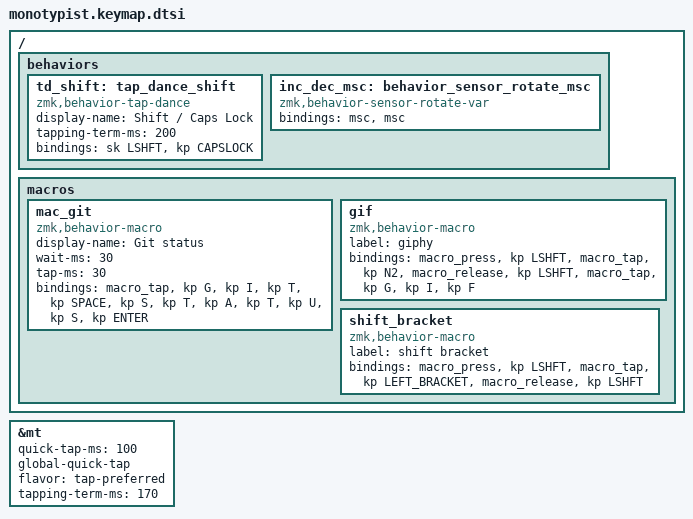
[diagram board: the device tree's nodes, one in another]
/*
 *     __  __                  _____            _     _ 
 *    |  \/  | ___  _ __   ___|_   _|   _ _ __ (_)___| |_ 
 *    | |\/| |/ _ \| '_ \ / _ \ | || | | | '_ \| / __| __|
 *    | |  | | (_) | | | | (_) || || |_| | (_) | \__ \ |_ 
 *    |_|  |_|\___/|_| |_|\___/ |_| \__, | .__/|_|___/\__|
 *    \_______________________/     |___/|_|              
 *
 * The keymap every MonoTypist language shares: behaviours, macros, and the two generated parts of one
 * language. A language's keymap (config/boards/shields/v4_2_<lang>/v4_2_<lang>.keymap, itself written by
 * tools/gen-keymap.mjs) names those parts in MT_COMBOS and MT_LAYERS and then includes this file.
 */

#if !defined(MT_COMBOS) || !defined(MT_LAYERS)
#error "Include this file from a language's keymap, which defines MT_COMBOS and MT_LAYERS"
#endif

#include <behaviors.dtsi>
#include <behaviors/lpos.dtsi>
#include <dt-bindings/zmk/keys.h>
#include <dt-bindings/zmk/pointing.h>
#include <dt-bindings/zmk/bt.h>
#include <dt-bindings/zmk/outputs.h>

#ifndef SIMPLE_MODE
#define SIMPLE_MODE 0
#endif

#define BASE 0
#define BLUE 1
#define RED 2
#define ORANGE 3
#define NAV  4
#define SYM  5
#define ADJ  6

&mt {
  quick-tap-ms = <100>;
  global-quick-tap;
  flavor = "tap-preferred";
  tapping-term-ms = <170>;
};

/ {
    // The language's combos, generated from layout/<lang>.json: every "letter key + thumb key".
    #include MT_COMBOS
//   combos {
//           compatible = "zmk,combos";
//           combo_esc {
//               timeout-ms = <50>;
//               key-positions = <0 1>;
//               bindings = <&kp ESC>;
//           };
//   };


    behaviors {
        td_shift: tap_dance_shift {
            compatible = "zmk,behavior-tap-dance";
            display-name = "Shift / Caps Lock"; // the name ZMK Studio and the site's editor know it by
            #binding-cells = <0>;
            tapping-term-ms = <200>;
            bindings = <&sk LSHFT>, <&kp CAPSLOCK>;
        };

        inc_dec_msc: behavior_sensor_rotate_msc {
            compatible = "zmk,behavior-sensor-rotate-var";
            #sensor-binding-cells = <2>;
            bindings = <&msc>, <&msc>;
        };
    };

    macros {
        mac_git: mac_git {
            compatible = "zmk,behavior-macro";
            display-name = "Git status"; // the name ZMK Studio and the site's editor know it by
            #binding-cells = <0>;
            wait-ms = <30>;
            tap-ms = <30>;
            bindings = <&macro_tap &kp G &kp I &kp T &kp SPACE &kp S &kp T &kp A &kp T &kp U &kp S &kp ENTER>;
        };

        gif: gif {
            label = "giphy";
            compatible = "zmk,behavior-macro";
            #binding-cells = <0>;
            bindings
                = <&macro_press &kp LSHFT>
                , <&macro_tap &kp N2>
                , <&macro_release &kp LSHFT>
                , <&macro_tap &kp G &kp I &kp F>
                ;
        };
        shift_bracket: shift_bracket {
            label = "shift bracket";
            compatible = "zmk,behavior-macro";
            #binding-cells = <0>;
            bindings
                = <&macro_press &kp LSHFT>
                , <&macro_tap &kp LEFT_BRACKET>
                , <&macro_release &kp LSHFT> 
                ;
        };
    };

    // The language's layer tables, generated from layout/<lang>.json.
    #include MT_LAYERS
};
